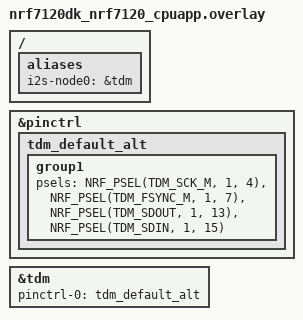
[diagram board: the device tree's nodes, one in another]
/* Test requires GPIO loopback:
 * P1.13 - P1.15
 */

/ {
	aliases {
		i2s-node0 = &tdm;
	};
};

&pinctrl {
	tdm_default_alt: tdm_default_alt {
		group1 {
			psels = <NRF_PSEL(TDM_SCK_M, 1, 4)>,
				<NRF_PSEL(TDM_FSYNC_M, 1, 7)>,
				<NRF_PSEL(TDM_SDOUT, 1, 13)>,
				<NRF_PSEL(TDM_SDIN, 1, 15)>;
		};
	};
};

&tdm {
	status = "okay";
	pinctrl-0 = <&tdm_default_alt>;
	pinctrl-names = "default";
};
